# SAMA7G54D1GN0 register map
Vendor: Microchip Technology; Series: SAMA7G5; File version: 0
Registers are 32-bit, read-write, reset 0x0 unless marked. A register's access mark holds for its fields unless they carry their own. Offsets are from the block's base; [hi:lo] are bit positions; {n}, {i} and the like mark numbered series; 'fields as' and 'values as' point back to an identical list.

## SCKC — Slow Clock Controller
Base 0xE001D050
0x00 CR reset 0x1 — Slow Clock Controller Configuration Register
  [24] TD_OSCSEL — Timing Domain Slow Clock Selector
    0=RC (Slow clock of the timing domain is driven by the embedded Always-on 64 kHz (typical) RC oscillator.); 1=XTAL (Slow clock of the timing domain is driven by the 32.768 kHz crystal oscillator.)

## SFR — Special Function Registers
Base 0xE1624000
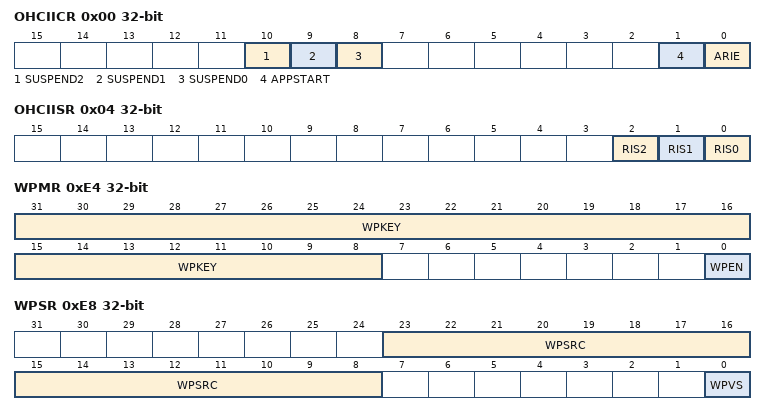
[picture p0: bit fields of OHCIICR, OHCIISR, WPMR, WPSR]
0x00 OHCIICR — OHCI Interrupt Configuration Register
  [10] SUSPEND2 — USB PORT 2
    0=Suspends controlled by EHCI-OCHI; 1=Forces the suspend for PORTx
  [9] SUSPEND1 — USB PORT 1
    values as SUSPEND2
  [8] SUSPEND0 — USB PORT 0
    values as SUSPEND2
  [1] APPSTART
  [0] ARIE — OHCI Asynchronous Resume Interrupt Enable
    0=Interrupt is disabled; 1=Interrupt is enabled
0x04 OHCIISR ro — OHCI Interrupt Status Register
  [all] fields
    0=OHCI port resume not detected; 1=OHCI port resume detected
  [2] RIS2 — OHCI Resume Interrupt Status Port 2
  [1] RIS1 — OHCI Resume Interrupt Status Port 1
  [0] RIS0 — OHCI Resume Interrupt Status Port 0
0xE4 WPMR — Write Protection Mode Register
  [31:8] WPKEY — Write Protection Key
    0x534652=PASSWD (Writing any other value in this field aborts the write operation of the WPEN bit. Always reads as 0.)
  [0] WPEN — Write Protection Enable
    0=Disables the write protection if WPKEY value corresponds to 0x534652 ('SFR' in ASCII); 1=Enables the write protection if WPKEY value corresponds to 0x534652 ('SFR' in ASCII)
0xE8 WPSR ro — Write Protection Status Register
  [23:8] WPSRC — Write Protection Source
  [0] WPVS — Write Protection Violation Status
    0=No write protection violation has occurred since the last read of SFR_WPSR; 1=A write protection violation has occurred since the last read of SFR_WPSR. If this violation is an unauthorized attempt to write a protected register, the associated violation is reported into field WPSRC.
0x2020 EHCIOHCI
  [0] EHCICLK — EHCI Clock Mode
    0=FREECLK of Port A is used to drive the EHCI clock; 1=PHYCLK of Port A is used to drive the EHCI clock
0x202C UDDRC
  [0] DIS_DECERR — Disable Decode Error
    0=Enables decode error when reading a non-existing register in the DDR controller Configuration Address Space; 1=Disables decode error when reading a non-existing register in the DDR controller Configuration Address Space
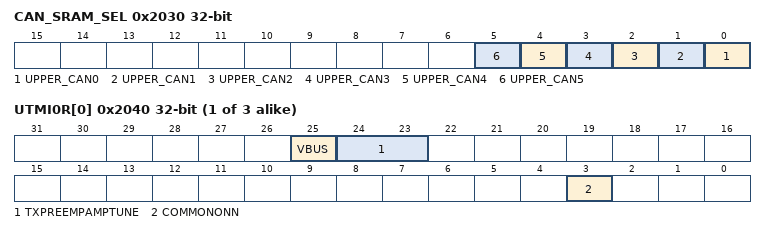
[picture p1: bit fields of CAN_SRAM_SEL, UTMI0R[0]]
0x2030 CAN_SRAM_SEL — SFR CAN SRAM Selection Register
  [all] fields
    0=CANx accesses the lower 64K SRAM; 1=CANx accesses the upper 64K SRAM
  [n] UPPER_CAN{n} (n=0..5) — CANx Upper 64K SRAM Selection
{0x2040+4i} UTMI0R[{i}] (i=0..2) — UTMI0 Configuration Register (port = 0)
  [25] VBUS — VBUS Valid Indicator
    0=The VBUS signal is not valid, and the pull-up resistor on D+ is disabled; 1=The VBUS signal is valid, and the pull-up resistor on D+ is enabled
  [24:23] TXPREEMPAMPTUNE — HS Transmitter Pre-Emphasis Current Control
  [3] COMMONONN — Common Block Power-Down Control
    0=PLL blocks remain powered; 1=PLL blocks are powered down

## SFRBU — Special Function Register Backup
Base 0xE0008000
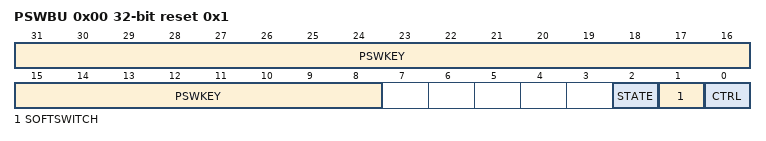
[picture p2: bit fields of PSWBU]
0x00 PSWBU reset 0x1 — VDDBU Power Switch Control
  [31:8] PSWKEY — Specific Value Mandatory to Allow Writing of Other Register Bits (Write-only)
    0x4BD20C=PASSWD (Writing any other value in this field aborts the write operation in the SFRBU_PSWBU register. Always reads as 0.)
  [2] STATE — VDDBU Power Switch State (Read-only)
    0=VBAT (The VDDBU supply source is VBAT.); 1=VDDIN33 (The VDDBU supply source is VDDIN33.)
  [1] SOFTSWITCH — VDDBU Power Switch Source Selection
    values as STATE
  [0] CTRL — VDDBU Power Switch Control
    0=HARD (The VDDBU power switch is controlled by hardware (the SOFTSWITCH bit has no action).); 1=SOFT (The VDDBU power switch is controlled by software (the SOFTSWITCH bit has an action).)
0x10 DDRPWR — DDR Power Control
  [0] RETENTION — SDRAM I/Os Retention
